# STM32H7RSxx register map
File version: 0.2
CPU: CM7 r0p1, little endian, MPU, FPU, 4 interrupt priority bits
Registers are 32-bit, read-write, reset 0x0 unless marked. A register's access mark holds for its fields unless they carry their own. Offsets are from the block's base; [hi:lo] are bit positions; lines under a group give offsets from that group; {n}, {i} and the like mark numbered series; 'fields as' and 'values as' point back to an identical list.

## ETH (part 2 of 4) — Ethernet register block
Base 0x40028000
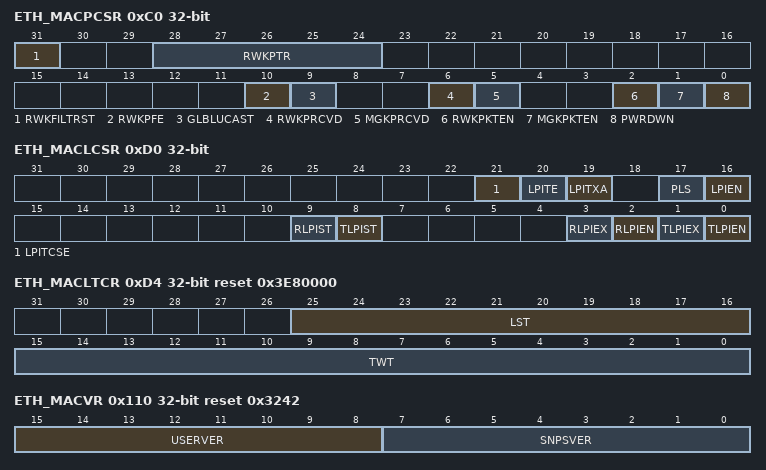
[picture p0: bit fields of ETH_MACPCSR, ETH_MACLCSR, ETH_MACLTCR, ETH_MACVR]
0xC0 ETH_MACPCSR access per field — PMT control status register
  [31] RWKFILTRST rw — Remote wakeup Packet Filter Register Pointer Reset When this bit is set, the remote wakeup packet filter register pointer is reset to 0. It is automatically cleared after 1 clock cycle.
  [28:24] RWKPTR ro — Remote wakeup FIFO Pointer This field gives the current value (0 to 7) of the Remote wakeup Packet Filter register pointer. When the value of this pointer is equal to 7, the contents of the Remote wakeup Packet Filter Register are transferred to the eth_mii_rx_clk domain when a Write occurs to that register.
  [10] RWKPFE rw — Remote wakeup Packet Forwarding Enable When this bit is set along with RWKPKTEN, the MAC receiver drops all received frames until it receives the expected wakeup frame. All frames after that event including the received wakeup frame are forwarded to application. This bit is then self-cleared on receiving the wakeup packet. The application can also clear this bit before the expected wakeup frame is received. In such cases, the MAC reverts to the default behavior where packets received are forwarded to the application. This bit must only be set when RWKPKTEN is set high and PWRDWN is set low. The setting of this bit has no effect when PWRDWN is set high. Note: If Magic Packet Enable and wakeup Frame Enable are both set along with setting of this bit and Magic Packet is received prior to wakeup frame, this bit is self-cleared on receiving Magic Packet, the received Magic packet is dropped, and all frames after received Magic Packet are forwarded to application.
  [9] GLBLUCAST rw — Global Unicast When this bit set, any unicast packet filtered by the MAC (DAF) address recognition is detected as a remote wakeup packet.
  [6] RWKPRCVD ro — Remote wakeup Packet Received When this bit is set, it indicates that the power management event is generated because of the reception of a remote wakeup packet. This bit is cleared when this register is read.
  [5] MGKPRCVD rw read-clears — Magic Packet Received When this bit is set, it indicates that the power management event is generated because of the reception of a magic packet. This bit is cleared when this register is read (or write of 1 when RCWE bit in CSR software control register (ETH_MACCSRSWCR) is set).
  [2] RWKPKTEN rw — Remote wakeup Packet Enable When this bit is set, a power management event is generated when the MAC receives a remote wakeup packet.
  [1] MGKPKTEN rw — Magic Packet Enable When this bit is set, a power management event is generated when the MAC receives a magic packet.
  [0] PWRDWN rw — Power Down When this bit is set, the MAC receiver drops all received packets until it receives the expected magic packet or remote wakeup packet. This bit is then self-cleared and the power-down mode is disabled. The software can clear this bit before the expected magic packet or remote wakeup packet is received. The packets received by the MAC after this bit is cleared are forwarded to the application. This bit must only be set when the Magic Packet Enable, Global Unicast, or Remote wakeup Packet Enable bit is set high. Note: You can gate-off the CSR clock during the power-down mode. However, when the CSR clock is gated-off, you cannot perform any read or write operations on this register. Therefore, the Software cannot clear this bit.
0xC4 ETH_MACRWKPFR — Remote wakeup packet filter register
  [31:0] MACRWKPFR — Remote wakeup packet filter Refer to Table 532, Table 533 and Table 534 for details on register content and programming sequence.
0xD0 ETH_MACLCSR access per field — LPI control and status register
  [21] LPITCSE rw — LPI Tx Clock Stop Enable When this bit is set, the MAC asserts sbd_tx_clk_gating_ctrl_o signal high after it enters Tx LPI mode to indicate that the Tx clock to MAC can be stopped. When this bit is reset, the MAC does not assert sbd_tx_clk_gating_ctrl_o signal high after it enters Tx LPI mode. If RGMII Interface is selected, the Tx clock is required for transmitting the LPI pattern. The Tx Clock cannot be gated and so the LPITCSE bit cannot be programmed.
  [20] LPITE rw — LPI Timer Enable This bit controls the automatic entry of the MAC Transmitter into and exit out of the LPI state. When LPITE, LPITXA and LPIEN bits are set, the MAC Transmitter enters LPI state only when the complete MAC TX data path is IDLE for a period indicated by the ETH_MACLETR register. After entering LPI state, if the data path becomes non-IDLE (due to a new packet being accepted for transmission), the Transmitter exits LPI state but does not clear LPIEN bit. This enables the re-entry into LPI state when it is IDLE again. When LPITE is 0, the LPI Auto timer is disabled and MAC Transmitter enters LPI state based on the settings of LPITXA and LPIEN bit descriptions.
  [19] LPITXA rw — LPI Tx Automate This bit controls the behavior of the MAC when it is entering or coming out of the LPI mode on the Transmit side. If the LPITXA and LPIEN bits are set to 1, the MAC enters the LPI mode only after all outstanding packets (in the core) and pending packets (in the application interface) have been transmitted. The MAC comes out of the LPI mode when the application sends any packet for transmission or the application issues a Tx FIFO Flush command. In addition, the MAC automatically clears the LPIEN bit when it exits the LPI state. If Tx FIFO Flush is set in the FTQ bit of ETH_MTLTxQOMR, when the MAC is in the LPI mode, it exits the LPI mode. When this bit is 0, the LPIEN bit directly controls behavior of the MAC when it is entering or coming out of the LPI mode.
  [17] PLS rw — PHY Link Status This bit indicates the link status of the PHY. The MAC Transmitter asserts the LPI pattern only when the link status is up (OKAY) at least for the time indicated by the LPI LS TIMER. When this bit is set, the link is considered to be okay (UP) and when this bit is reset, the link is considered to be down.
  [16] LPIEN rw — LPI Enable When this bit is set, it instructs the MAC Transmitter to enter the LPI state. When this bit is reset, it instructs the MAC to exit the LPI state and resume normal transmission. This bit is cleared when the LPITXA bit is set and the MAC exits the LPI state because of the arrival of a new packet for transmission.
  [9] RLPIST ro — Receive LPI State When this bit is set, it indicates that the MAC is receiving the LPI pattern on the MII interface.
  [8] TLPIST ro — Transmit LPI State When this bit is set, it indicates that the MAC is transmitting the LPI pattern on the MII interface.
  [3] RLPIEX ro — Receive LPI Exit When this bit is set, it indicates that the MAC Receiver has stopped receiving the LPI pattern on the MII interface, exited the LPI state, and resumed the normal reception. This bit is cleared by a read into this register (or write of 1 when RCWE bit in CSR software control register (ETH_MACCSRSWCR) is set). Note: This bit may not be set if the MAC stops receiving the LPI pattern for a very short duration, such as, less than three clock cycles of CSR clock.
  [2] RLPIEN ro — Receive LPI Entry When this bit is set, it indicates that the MAC Receiver has received an LPI pattern and entered the LPI state. This bit is cleared by a read into this register (or write of 1 when RCWE bit in CSR software control register (ETH_MACCSRSWCR) is set). Note: This bit may not be set if the MAC stops receiving the LPI pattern for a very short duration, such as, less than three clock cycles of CSR clock.
  [1] TLPIEX ro — Transmit LPI Exit When this bit is set, it indicates that the MAC transmitter exited the LPI state after the application cleared the LPIEN bit and the LPI TW Timer has expired. This bit is cleared by a read into this register (or write of 1 when RCWE bit in CSR software control register (ETH_MACCSRSWCR) is set).
  [0] TLPIEN ro — Transmit LPI Entry When this bit is set, it indicates that the MAC Transmitter has entered the LPI state because of the setting of the LPIEN bit. This bit is cleared by a read into this register (or write of 1 when RCWE bit in CSR software control register (ETH_MACCSRSWCR) is set).
0xD4 ETH_MACLTCR reset 0x3E80000 — LPI timers control register
  [25:16] LST — LPI LS Timer This field specifies the minimum time (in milliseconds) for which the link status from the PHY should be up (OKAY) before the LPI pattern can be transmitted to the PHY. The MAC does not transmit the LPI pattern even when the LPIEN bit is set unless the LPI LS Timer reaches the programmed terminal count. The default value of the LPI LS Timer is 1000 (1 sec) as defined in the IEEE standard.
  [15:0] TWT — LPI TW Timer This field specifies the minimum time (in microseconds) for which the MAC waits after it stops transmitting the LPI pattern to the PHY and before it resumes the normal transmission. The TLPIEX status bit is set after the expiry of this timer.
0xD8 ETH_MACLETR — LPI entry timer register
  [19:0] LPIET — LPI Entry Timer This field specifies the time in microseconds the MAC waits to enter LPI mode, after it has transmitted all the frames. This field is valid and used only when LPITE and LPITXA are set to 1. Bits [2:0] are read-only so that the granularity of this timer is in steps of 8 micro-seconds.
0xDC ETH_MAC1USTCR — One-microsecond-tick counter register
  [11:0] TIC_1US_CNTR — 1 �s tick Counter The application must program this counter so that the number of clock cycles of CSR clock is 1 �s (subtract 1 from the value before programming). For example if the CSR clock is 100 MHz then this field needs to be programmed to 100 - 1 = 99 (which is 0x63). This is required to generate the 1 �s events that are used to update some of the EEE related counters.
0x110 ETH_MACVR ro reset 0x3242 — Version register
  [15:8] USERVER — ST-defined version
  [7:0] SNPSVER — IP version
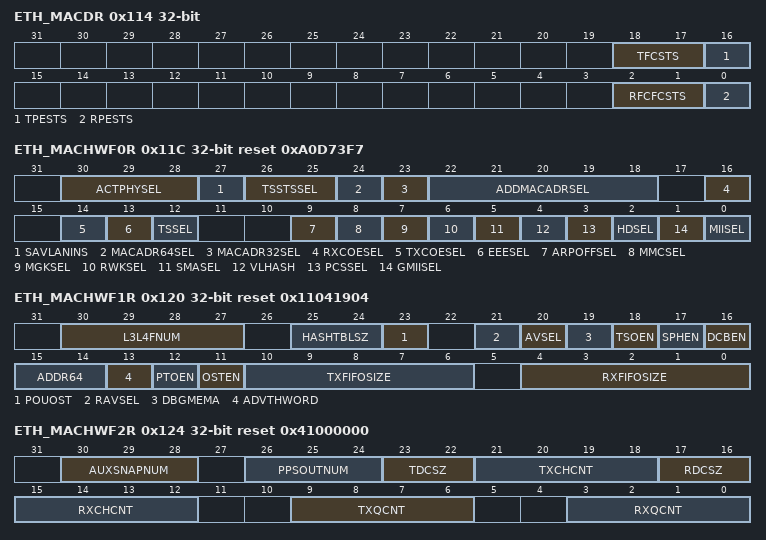
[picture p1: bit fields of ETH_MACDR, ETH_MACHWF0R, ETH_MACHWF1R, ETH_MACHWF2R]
0x114 ETH_MACDR ro — Debug register
  [18:17] TFCSTS — MAC Transmit Packet Controller Status This field indicates the state of the MAC Transmit Packet Controller module: Status of the previous packet IPG or backoff period to be over
    0=Idle state; 1=Waiting for one of the following:; 2=Generating and transmitting a Pause control packet (in Full-duplex mode); 3=Transferring input packet for transmission
  [16] TPESTS — MAC MII Transmit Protocol Engine Status When this bit is set, it indicates that the MAC MII transmit protocol engine is actively transmitting data, and it is not in the Idle state.
  [2:1] RFCFCSTS — MAC Receive Packet Controller FIFO Status When this bit is set, this field indicates the active state of the small FIFO Read and Write controllers of the MAC Receive Packet Controller module.
  [0] RPESTS — MAC MII Receive Protocol Engine Status When this bit is set, it indicates that the MAC MII receive protocol engine is actively receiving data, and it is not in the Idle state.
0x11C ETH_MACHWF0R ro reset 0xA0D73F7 — HW feature 0 register
  [30:28] ACTPHYSEL — Active PHY Selected When you have multiple PHY interfaces in your configuration, this field indicates the sampled value of phy_intf_sel_i during reset de-assertion: Others: Reserved, must not be used
    0=GMII or MII; 1=RGMII; 2=SGMII; 3=TBI; 4=RMII; 5=RTBI; 6=SMII
  [27] SAVLANINS — Source Address or VLAN Insertion Enable This bit is set to 1 when the Enable SA and VLAN Insertion on Tx option is selected
  [26:25] TSSTSSEL — Timestamp System Time Source This bit indicates the source of the Timestamp system time: This bit is set to 1 when the Enable IEEE 1588 Timestamp Support option is selected
    1=Internal; 2=External; 3=Both; 0=Reserved, must not be used
  [24] MACADR64SEL — MAC Addresses 64-127 Selected This bit is set to 1 when the Enable Additional 64 MAC Address Registers (64-127) option is selected
  [23] MACADR32SEL — MAC Addresses 32-63 Selected This bit is set to 1 when the Enable Additional 32 MAC Address Registers (32-63) option is selected
  [22:18] ADDMACADRSEL — MAC Addresses 1-31 Selected This bit is set to 1 when the Enable Additional 1-31 MAC Address Registers option is selected
  [16] RXCOESEL — Receive Checksum Offload Enabled This bit is set to 1 when the Enable Receive TCP/IP Checksum Check option is selected
  [14] TXCOESEL — Transmit Checksum Offload Enabled This bit is set to 1 when the Enable Transmit TCP/IP Checksum Insertion option is selected
  [13] EEESEL — Energy Efficient Ethernet Enabled This bit is set to 1 when the Enable Energy Efficient Ethernet (EEE) option is selected
  [12] TSSEL — IEEE 1588-2008 Timestamp Enabled This bit is set to 1 when the Enable IEEE 1588 Timestamp Support option is selected
  [9] ARPOFFSEL — ARP Offload Enabled This bit is set to 1 when the Enable IPv4 ARP Offload option is selected
  [8] MMCSEL — RMON Module Enable This bit is set to 1 when the Enable MAC management counters (MMC) option is selected
  [7] MGKSEL — PMT Magic Packet Enable This bit is set to 1 when the Enable Magic Packet Detection option is selected
  [6] RWKSEL — PMT Remote Wakeup Packet Enable This bit is set to 1 when the Enable Remote wakeup Packet Detection option is selected
  [5] SMASEL — SMA (MDIO) Interface This bit is set to 1 when the Enable Station Management (MDIO Interface) option is selected
  [4] VLHASH — VLAN Hash Filter Selected This bit is set to 1 when the Enable VLAN Hash Table Based Filtering option is selected
  [3] PCSSEL — PCS Registers (TBI, SGMII, or RTBI PHY interface) This bit is set to 1 when the TBI, SGMII, or RTBI PHY interface option is selected
  [2] HDSEL — Half-duplex Support This bit is set to 1 when the Half-duplex mode is selected
  [1] GMIISEL — 1000 Mbps Support This bit is set to 1 when 1000 Mbps is selected as operating mode.
  [0] MIISEL — 10 or 100 Mbps Support This bit is set to 1 when 10/100 Mbps is selected as operating mode.
0x120 ETH_MACHWF1R ro reset 0x11041904 — HW feature 1 register
  [30:27] L3L4FNUM — Total number of L3 or L4 Filters This field indicates the total number of L3 or L4 filters: ..
    0=No L3 or L4 Filter; 1=1 L3 or L4 Filter; 2=2 L3 or L4 Filters; 8=8 L3 or L4
  [25:24] HASHTBLSZ — Hash Table Size This field indicates the size of the Hash table:
    0=No Hash table; 1=64; 2=128; 3=256
  [23] POUOST — One Step for PTP over UDP/IP Feature Enable This bit is set to 1 when the Enable one step timestamp for PTP over UDP/IP feature is selected.
  [21] RAVSEL — Rx Side Only AV Feature Enable This bit is set to 1 when the Enable Audio video bridging option on Rx Side Only is selected.
  [20] AVSEL — AV Feature Enable This bit is set to 1 when the Enable Audio video bridging option is selected.
  [19] DBGMEMA — DMA Debug Registers Enable This bit is set to 1 when the Debug Mode Enable option is selected
  [18] TSOEN — TCP Segmentation Offload Enable This bit is set to 1 when the Enable TCP Segmentation Offloading for TCP/IP Packets option is selected
  [17] SPHEN — Split Header Feature Enable This bit is set to 1 when the Enable Split Header Structure option is selected
  [16] DCBEN — DCB Feature Enable This bit is set to 1 when the Enable Data Center Bridging option is selected
  [15:14] ADDR64 — Address width This field indicates the configured address width. Others: Reserved, must not be used
    0=32 bits
  [13] ADVTHWORD — IEEE 1588 High Word Register Enable This bit is set to 1 when the Add IEEE 1588 Higher Word Register option is selected
  [12] PTOEN — PTP Offload Enable This bit is set to 1 when the Enable PTP Timestamp Offload Feature is selected.
  [11] OSTEN — One-Step Timestamping Enable This bit is set to 1 when the Enable One-Step Timestamp Feature is selected.
  [10:6] TXFIFOSIZE — MTL Transmit FIFO Size This field contains the configured value of MTL Tx FIFO in bytes expressed as Log to base 2 minus 7, that is, Log2(TXFIFO_SIZE) -7: 01011 to 11111: Reserved, must not be used
    0=128 bytes; 1=256 bytes; 2=512 bytes; 3=1,024 bytes; 4=2,048 bytes; 5=4,096 bytes; 6=8,192 bytes; 7=16,384 bytes; 8=32 Kbytes; 9=64 Kbytes; 10=128 Kbytes
  [4:0] RXFIFOSIZE — MTL Receive FIFO Size This field contains the configured value of MTL Rx FIFO in bytes expressed as Log to base 2 minus 7, that is, Log2(RXFIFO_SIZE) -7: 01100 to 11111: Reserved, must not be used
    0=128 bytes; 1=256 bytes; 2=512 bytes; 3=1,024 bytes; 4=2,048 bytes; 5=4,096 bytes; 6=8,192 bytes; 7=16,384 bytes; 8=32 Kbytes; 9=64 Kbytes; 10=128 Kbytes; 11=256 Kbytes
0x124 ETH_MACHWF2R ro reset 0x41000000 — HW feature 2 register
  [30:28] AUXSNAPNUM — Number of Auxiliary Snapshot Inputs This field indicates the number of auxiliary snapshot inputs: 101 to 111: Reserved, must not be used
    0=No auxiliary input; 1=1 auxiliary input; 2=2 auxiliary inputs; 3=3 auxiliary inputs; 4=4 auxiliary inputs
  [26:24] PPSOUTNUM — Number of PPS Outputs This field indicates the number of PPS outputs: 101 to 111: Reserved, must not be used
    0=No PPS output; 1=1 PPS output; 2=2 PPS outputs; 3=3 PPS outputs; 4=4 PPS outputs
  [23:22] TDCSZ — Tx DMA Descriptor Cache Size in terms of 16-byte descriptors
    0=Cache not configured; 1=Four 16-byte descriptors; 2=Eight 16-byte descriptors; 3=Sixteen 16-byte descriptors
  [21:18] TXCHCNT — Number of DMA Transmit Channels This field indicates the number of DMA Transmit channels: ..
    0=1 DMA Tx Channel; 1=2 DMA Tx Channels; 7=8 DMA Tx
  [17:16] RDCSZ — Rx DMA Descriptor Cache Size in terms of 16-byte descriptors
    values as TDCSZ
  [15:12] RXCHCNT — Number of DMA Receive Channels This field indicates the number of DMA Receive channels: ..
    0=1 DMA Rx Channel; 1=2 DMA Rx Channels; 7=8 DMA Rx
  [9:6] TXQCNT — Number of MTL Transmit Queues This field indicates the number of MTL Transmit queues: ..
    0=1 MTL Tx queue; 1=2 MTL Tx queues; 7=8 MTL Tx
  [3:0] RXQCNT — Number of MTL Receive Queues This field indicates the number of MTL Receive queues: ..
    0=1 MTL Rx queue; 1=2 MTL Rx queues; 7=8 MTL Rx
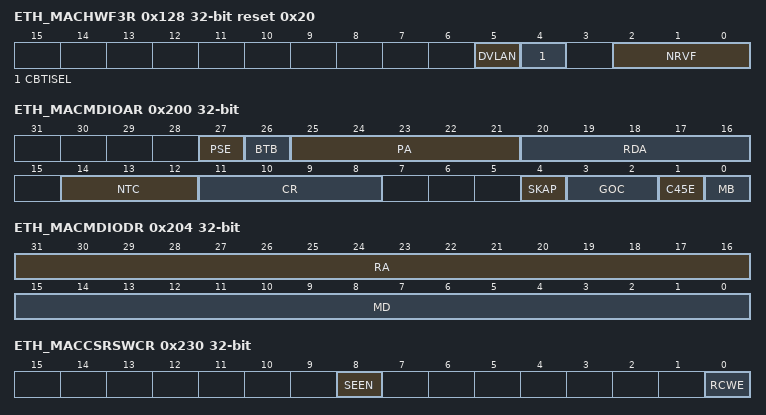
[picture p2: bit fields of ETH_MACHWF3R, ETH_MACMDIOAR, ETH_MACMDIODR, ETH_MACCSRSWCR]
0x128 ETH_MACHWF3R ro reset 0x20 — HW feature 3 register
  [5] DVLAN — Double VLAN processing enable This bit is set to 1 when Double VLAN processing is enabled.
  [4] CBTISEL — Queue/Channel based VLAN tag insertion on Tx enable This bit is set to 1 when the Enable Queue/Channel based VLAN tag insertion on Tx feature is selected.
  [2:0] NRVF — Number of Extended VLAN Tag Filters Enabled This field indicates the Number of Extended VLAN Tag Filters selected: 110 to 111: Reserved, must not be used
    0=No Extended Rx VLAN Filters; 1=4 Extended Rx VLAN Filters; 2=8 Extended Rx VLAN Filters; 3=16 Extended Rx VLAN Filters; 4=24 Extended Rx VLAN Filters; 5=32 Extended Rx VLAN Filters
0x200 ETH_MACMDIOAR — MDIO address register
  [27] PSE — Preamble Suppression Enable When this bit is set, the SMA suppresses the 32-bit preamble and transmit MDIO frames with only 1 preamble bit. When this bit is 0, the MDIO frame always has 32 bits of preamble as defined in the IEEE specifications.
  [26] BTB — Back to Back transactions When this bit is set and the NTC has value greater than 0, then the MAC informs the completion of a read or write command at the end of frame transfer (before the trailing clocks are transmitted). The software can thus initiate the next command which is executed immediately irrespective of the number trailing clocks generated for the previous frame. When this bit is reset, then the read/write command completion (MII busy is cleared) only after the trailing clocks are generated. In this mode, it is ensured that the NTC is always generated after each frame. This bit must not be set when NTC=0.
  [25:21] PA — Physical Layer Address This field indicates which Clause 22 PHY devices (out of 32 devices) the MAC is accessing. This field indicates which Clause 45 capable PHYs (out of 32 PHYs) the MAC is accessing.
  [20:16] RDA — Register/Device Address These bits select the PHY register in selected Clause 22 PHY device. These bits select the Device (MMD) in selected Clause 45 capable PHY.
  [14:12] NTC — Number of Training Clocks This field controls the number of trailing clock cycles generated on ETH_MDC after the end of transmission of MDIO frame. The valid values can be from 0 to 7. Programming the value to 011 indicates that there are additional three clock cycles on the MDC line after the end of MDIO frame transfer.
  [11:8] CR — CSR Clock Range The CSR Clock Range selection determines the frequency of the MDC clock according to the CSR clock frequency used in your design: 0110 to 0111: Reserved, must not be used The suggested range of CSR clock frequency applicable for each value (when Bit 11 = 0) ensures that the MDC clock is approximately between 1.0 MHz to 2.5 MHz frequency range. When Bit 11 is set, you can achieve a higher frequency of the MDC clock than the frequency limit of 2.5 MHz (specified in the IEEE 802.3) and program a clock divider of lower value. For example, when CSR clock is of 100 MHz frequency and you program these bits to 1010, the resultant MDC clock is of 12.5 MHz which is above the range specified in IEEE 802.3. Program the following values only if the interfacing chips support faster MDC clocks:
    0=CSR clock = 60-100 MHz; MDC clock = CSR clock/42; 1=CSR clock = 100-150 MHz; MDC clock = CSR clock/62; 2=CSR clock = 20-35 MHz; MDC clock = CSR clock/16; 3=CSR clock = 35-60 MHz; MDC clock = CSR clock/26; 4=CSR clock = 150-250 MHz; MDC clock = CSR clock/102; 5=CSR clock = 250-300 MHz; MDC clock = CSR clock/124; 8=CSR clock/4; 9=CSR clock/6; 10=CSR clock/8; 11=CSR clock/10; 12=CSR clock/12; 13=CSR clock/14; 14=CSR clock/16; 15=CSR clock/18
  [4] SKAP — Skip Address Packet When this bit is set, the SMA does not send the address packets before read, write, or post-read increment address packets. This bit is valid only when C45E is set.
  [3:2] GOC — MII Operation Command This bit indicates the operation command to the PHY. When Clause 22 PHY is enabled, only Write and Read commands are valid.
    0=Reserved, must not be used; 1=Write; 2=Post Read Increment Address for Clause 45 PHY; 3=Read
  [1] C45E — Clause 45 PHY Enable When this bit is set, Clause 45 capable PHY is connected to MDIO. When this bit is reset, Clause 22 capable PHY is connected to MDIO.
  [0] MB — MII Busy The application sets this bit to instruct the SMA to initiate a Read or Write access to the MDIOS. The MAC clears this bit after the MDIO frame transfer is completed. Hence the software must not write or change any of the fields in MDIO address register (ETH_MACMDIOAR) and MDIO data register (ETH_MACMDIODR) as long as this bit is set. For write transfers, the application must first write 16-bit data in the MD field (and also RA field when C45E is set) in MDIO data register (ETH_MACMDIODR) register before setting this bit. When C45E is set, it should also write into the RA field of MDIO data register (ETH_MACMDIODR) before initiating a read transfer. When a read transfer is completed (MII busy=0), the data read from the PHY register is valid in the MD field of the MDIO data register (ETH_MACMDIODR). Note: Even if the addressed PHY is not present, there is no change in the functionality of this bit.
0x204 ETH_MACMDIODR — MDIO data register
  [31:16] RA — Register Address This field is valid only when C45E is set. It contains the Register Address in the PHY to which the MDIO frame is intended for.
  [15:0] MD — MII Data This field contains the 16-bit data value read from the PHY after a Management Read operation or the 16-bit data value to be written to the PHY before a Management Write operation.
0x210 ETH_MACARPAR — ARP address register
  [31:0] ARPPA — ARP Protocol Address This field contains the IPv4 Destination Address of the MAC. This address is used for perfect match with the Protocol Address of Target field in the received ARP packet.
0x230 ETH_MACCSRSWCR — CSR software control register
  [8] SEEN — Slave Error Response Enable When this bit is set, the MAC responds with a Slave Error for accesses to reserved registers in CSR space. When this bit is reset, the MAC responds with an Okay response to any register accessed from CSR space.
  [0] RCWE — Register Clear on Write 1 Enable When this bit is set, the access mode to some register fields changes to rc_w1 (clear on write) meaning that the application needs to set that respective bit to 1 to clear it. When this bit is reset, the access mode to these register fields remains rc_r (clear on read).
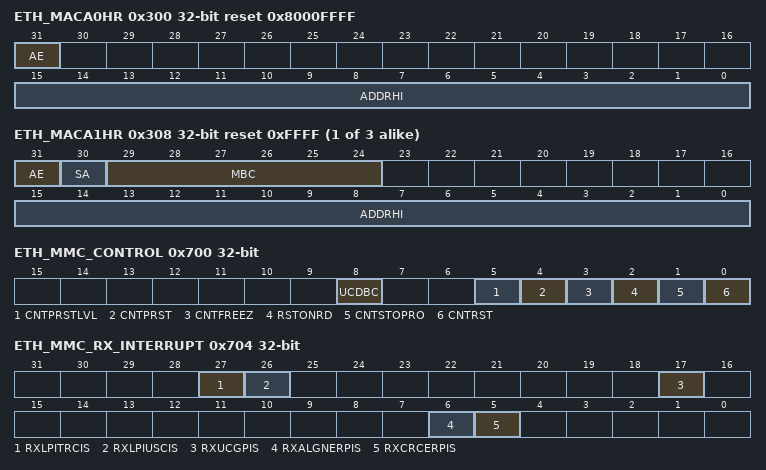
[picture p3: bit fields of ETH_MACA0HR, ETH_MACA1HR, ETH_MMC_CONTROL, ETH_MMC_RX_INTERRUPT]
0x300 ETH_MACA0HR access per field reset 0x8000FFFF — MAC Address 0 high register
  [31] AE ro — Address Enable This bit is always set to 1.
  [15:0] ADDRHI rw — MAC Address0[47:32] This field contains the upper 16 bits [47:32] of the first 6-byte MAC address. The MAC uses this field for filtering the received packets and inserting the MAC address in the Transmit Flow Control (Pause) Packets.
{0x304+8i} ETH_MACA{i}LR reset 0xFFFFFFFF (i=0..3) — MAC Address {i} low register
  [31:0] ADDRLO — MAC Address x [31:0] This field contains the lower 32 bits of the first 6-byte MAC address. The MAC uses this field for filtering the received packets and inserting the MAC address in the Transmit Flow Control (Pause) Packets.
{0x300+8i} ETH_MACA{i}HR reset 0xFFFF (i=1..3) — MAC Address {i} high register
  [31] AE — Address Enable When this bit is set, the address filter module uses the second MAC address for perfect filtering. When this bit is reset, the address filter module ignores the address for filtering.
  [30] SA — Source Address When this bit is set, the MAC Addressx[47:0] is used to compare with the SA fields of the received packet. When this bit is reset, the MAC Address x[47:0] is used to compare with the DA fields of the received packet.
    0=DA; 1=SA
  [29:24] MBC — Mask Byte Control These bits are mask control bits for comparing each of the MAC Address bytes. When set high, the MAC does not compare the corresponding byte of received DA or SA with the contents of MAC Address1 registers. Each bit controls the masking of the bytes as follows: Bit 29: ETH_MACAxHR[15:8] Bit 28: ETH_MACAxHR[7:0] Bit 27: ETH_MACAxLR[31:24] Bit 26: ETH_MACAxLR[23:16] Bit 25: ETH_MACAxLR[15:8] Bit 24: ETH_MACAxLR[7:0] You can filter a group of addresses (known as group address filtering) by masking one or more bytes of the address.
  [15:0] ADDRHI — MAC Address1 [47:32] This field contains the upper 16 bits[47:32] of the second 6-byte MAC address.
0x700 ETH_MMC_CONTROL — MMC control register
  [8] UCDBC — Update MMC Counters for Dropped Broadcast Packets The CNTRST bit has a higher priority than the CNTPRST bit. Therefore, when the software tries to set both bits in the same write cycle, all counters are cleared and the CNTPRST bit is not set. When set, the MAC updates all related MMC Counters for Broadcast packets that are dropped because of the setting of the DBF bit of Packet filtering control register (ETH_MACPFR). When reset, the MMC Counters are not updated for dropped Broadcast packets.
  [5] CNTPRSTLVL — Full-Half Preset When this bit is low and the CNTPRST bit is set, all MMC counters get preset to almost-half value. All octet counters get preset to 0x7FFF_F800 (Half 2Kbytes) and all packet-counters get preset to 0x7FFF_FFF0 (Half 16). When this bit is high and the CNTPRST bit is set, all MMC counters get preset to almost-full value. All octet counters get preset to 0xFFFF_F800 (Full 2Kbytes) and all packet-counters get preset to 0xFFFF_FFF0 (Full 16). For 16-bit counters, the almost-half preset values are 0x7800 and 0x7FF0 for the respective octet and packet counters. Similarly, the almost-full preset values for the 16-bit counters are 0xF800 and 0xFFF0.
  [4] CNTPRST — Counters Preset When this bit is set, all counters are initialized or preset to almost full or almost half according to the CNTPRSTLVL bit. This bit is cleared automatically after 1 clock cycle. This bit, along with the CNTPRSTLVL bit, is useful for debugging and testing the assertion of interrupts because of MMC counter becoming half-full or full.
  [3] CNTFREEZ — MMC Counter Freeze When this bit is set, it freezes all MMC counters to their current value. Until this bit is reset to 0, no MMC counter is updated because of any transmitted or received packet. If any MMC counter is read with the Reset on Read bit set, then that counter is also cleared in this mode.
  [2] RSTONRD — Reset on Read When this bit is set, the MMC counters are reset to zero after Read (self-clearing after reset). The counters are cleared when the least significant byte lane (Bits[7:0]) is read.
  [1] CNTSTOPRO — Counter Stop Rollover When this bit is set, the counter does not roll over to zero after reaching the maximum value.
  [0] CNTRST — Counters Reset When this bit is set, all counters are reset. This bit is cleared automatically after 1 clock cycle.
0x704 ETH_MMC_RX_INTERRUPT — MMC Rx interrupt register
  [27] RXLPITRCIS read-clears — MMC Receive LPI transition counter interrupt status This bit is set when the Rx LPI transition counter register (ETH_RX_LPI_TRAN_CNTR) counter reaches half of the maximum value or the maximum value.
  [26] RXLPIUSCIS read-clears — MMC Receive LPI microsecond counter interrupt status This bit is set when the Rx LPI microsecond counter register (ETH_RX_LPI_USEC_CNTR) counter reaches half of the maximum value or the maximum value.
  [17] RXUCGPIS read-clears — MMC Receive Unicast Good Packet Counter Interrupt Status This bit is set when the Rx unicast packets good register (ETH_RX_UNICAST_PACKETS_GOOD) counter reaches half of the maximum value or the maximum value.
  [6] RXALGNERPIS read-clears — MMC Receive Alignment Error Packet Counter Interrupt Status This bit is set when the Rx alignment error packets register (ETH_RX_ALIGNMENT_ERROR_PACKETS) counter reaches half of the maximum value or the maximum value.
  [5] RXCRCERPIS read-clears — MMC Receive CRC Error Packet Counter Interrupt Status This bit is set when the Rx CRC error packets register (ETH_RX_CRC_ERROR_PACKETS) counter reaches half of the maximum value or the maximum value.
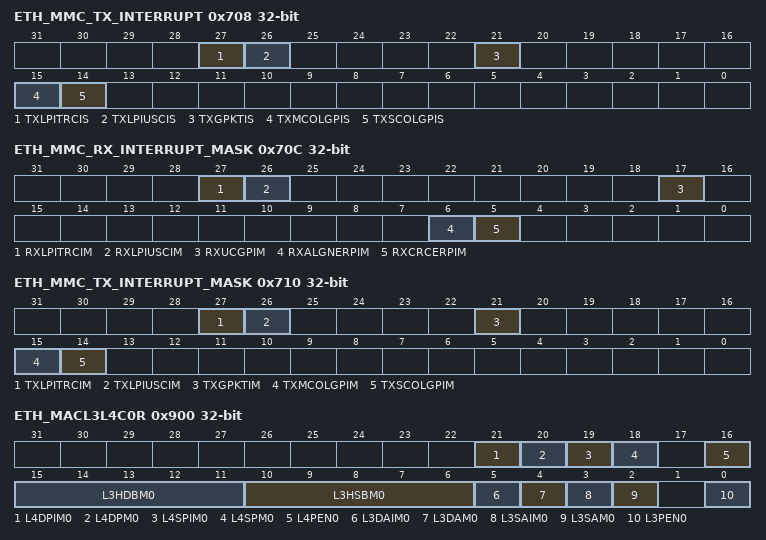
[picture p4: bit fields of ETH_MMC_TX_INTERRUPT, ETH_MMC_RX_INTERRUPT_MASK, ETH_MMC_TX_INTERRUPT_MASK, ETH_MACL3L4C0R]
0x708 ETH_MMC_TX_INTERRUPT — MMC Tx interrupt register
  [27] TXLPITRCIS read-clears — MMC Transmit LPI transition counter interrupt status This bit is set when the Tx LPI transition counter register (ETH_TX_LPI_TRAN_CNTR) counter reaches half of the maximum value or the maximum value.
  [26] TXLPIUSCIS read-clears — MMC Transmit LPI microsecond counter interrupt status This bit is set when the Tx LPI microsecond timer register (ETH_TX_LPI_USEC_CNTR) counter reaches half of the maximum value or the maximum value.
  [21] TXGPKTIS read-clears — MMC Transmit Good Packet Counter Interrupt Status This bit is set when the Tx packet count good register (ETH_TX_PACKET_COUNT_GOOD) counter reaches half of the maximum value or the maximum value.
  [15] TXMCOLGPIS read-clears — MMC Transmit Multiple Collision Good Packet Counter Interrupt Status This bit is set when the Tx multiple collision good packets register (ETH_TX_MULTIPLE_COLLISION_GOOD_PACKETS) counter reaches half of the maximum value or the maximum value.
  [14] TXSCOLGPIS read-clears — MMC Transmit Single Collision Good Packet Counter Interrupt Status This bit is set when the Tx single collision good packets register (ETH_TX_SINGLE_COLLISION_GOOD_PACKETS) counter reaches half of the maximum value or the maximum value.
0x70C ETH_MMC_RX_INTERRUPT_MASK — MMC Rx interrupt mask register
  [27] RXLPITRCIM — MMC Receive LPI transition counter interrupt Mask Setting this bit masks the interrupt when the Rx LPI transition counter register (ETH_RX_LPI_TRAN_CNTR) counter reaches half of the maximum value or the maximum value.
  [26] RXLPIUSCIM — MMC Receive LPI microsecond counter interrupt Mask Setting this bit masks the interrupt when the Rx LPI microsecond counter register (ETH_RX_LPI_USEC_CNTR) counter reaches half of the maximum value or the maximum value.
  [17] RXUCGPIM — MMC Receive Unicast Good Packet Counter Interrupt Mask Setting this bit masks the interrupt when the Rx unicast packets good register (ETH_RX_UNICAST_PACKETS_GOOD) counter reaches half of the maximum value or the maximum value.
  [6] RXALGNERPIM — MMC Receive Alignment Error Packet Counter Interrupt Mask Setting this bit masks the interrupt when the Rx alignment error packets register (ETH_RX_ALIGNMENT_ERROR_PACKETS) counter reaches half of the maximum value or the maximum value.
  [5] RXCRCERPIM — MMC Receive CRC Error Packet Counter Interrupt Mask Setting this bit masks the interrupt when the Rx CRC error packets register (ETH_RX_CRC_ERROR_PACKETS) counter reaches half of the maximum value or the maximum value.
0x710 ETH_MMC_TX_INTERRUPT_MASK — MMC Tx interrupt mask register
  [27] TXLPITRCIM — MMC Transmit LPI transition counter interrupt Mask Setting this bit masks the interrupt when the Tx LPI transition counter register (ETH_TX_LPI_TRAN_CNTR) counter reaches half of the maximum value or the maximum value.
  [26] TXLPIUSCIM — MMC Transmit LPI microsecond counter interrupt Mask Setting this bit masks the interrupt when the Tx LPI microsecond timer register (ETH_TX_LPI_USEC_CNTR) counter reaches half of the maximum value or the maximum value.
  [21] TXGPKTIM — MMC Transmit Good Packet Counter Interrupt Mask Setting this bit masks the interrupt when the Tx packet count good register (ETH_TX_PACKET_COUNT_GOOD) counter reaches half of the maximum value or the maximum value.
  [15] TXMCOLGPIM — MMC Transmit Multiple Collision Good Packet Counter Interrupt Mask Setting this bit masks the interrupt when the Tx multiple collision good packets register (ETH_TX_MULTIPLE_COLLISION_GOOD_PACKETS) counter reaches half of the maximum value or the maximum value.
  [14] TXSCOLGPIM — MMC Transmit Single Collision Good Packet Counter Interrupt Mask Setting this bit masks the interrupt when the Tx single collision good packets register (ETH_TX_SINGLE_COLLISION_GOOD_PACKETS) counter reaches half of the maximum value or the maximum value.
0x74C ETH_TX_SINGLE_COLLISION_GOOD_PACKETS ro — Tx single collision good packets register
  [31:0] TXSNGLCOLG — Tx Single Collision Good Packets This field indicates the number of successfully transmitted packets after a single collision in the Half-duplex mode.
0x750 ETH_TX_MULTIPLE_COLLISION_GOOD_PACKETS ro — Tx multiple collision good packets register
  [31:0] TXMULTCOLG — Tx Multiple Collision Good Packets This field indicates the number of successfully transmitted packets after multiple collisions in the Half-duplex mode.
0x768 ETH_TX_PACKET_COUNT_GOOD ro — Tx packet count good register
  [31:0] TXPKTG — Tx Packet Count Good This field indicates the number of good packets transmitted.
0x794 ETH_RX_CRC_ERROR_PACKETS ro — Rx CRC error packets register
  [31:0] RXCRCERR — Rx CRC Error Packets This field indicates the number of packets received with CRC error.
0x798 ETH_RX_ALIGNMENT_ERROR_PACKETS ro — Rx alignment error packets register
  [31:0] RXALGNERR — Rx Alignment Error Packets This field indicates the number of packets received with alignment (dribble) error. It is valid only in 10/100 mode.
0x7C4 ETH_RX_UNICAST_PACKETS_GOOD ro — Rx unicast packets good register
  [31:0] RXUCASTG — Rx Unicast Packets Good This field indicates the number of good unicast packets received.
0x7EC ETH_TX_LPI_USEC_CNTR ro — Tx LPI microsecond timer register
  [31:0] TXLPIUSC — Tx LPI Microseconds Counter This field indicates the number of microseconds Tx LPI is asserted. For every Tx LPI Entry and Exit, the Timer value can have an error of +/- 1 microsecond.
0x7F0 ETH_TX_LPI_TRAN_CNTR ro — Tx LPI transition counter register
  [31:0] TXLPITRC — Tx LPI Transition counter This field indicates the number of times Tx LPI Entry has occurred. Even if Tx LPI Entry occurs in Automate mode (because of LPITXA bit set in the LPI control and status register (ETH_MACLCSR)), the counter increments.
0x7F4 ETH_RX_LPI_USEC_CNTR ro — Rx LPI microsecond counter register
  [31:0] RXLPIUSC — Rx LPI Microseconds Counter This field indicates the number of microseconds Rx LPI is asserted. For every Rx LPI Entry and Exit, the Timer value can have an error of +/- 1 microsecond.
0x7F8 ETH_RX_LPI_TRAN_CNTR ro — Rx LPI transition counter register
  [31:0] RXLPITRC — Rx LPI Transition counter This field indicates the number of times Rx LPI Entry has occurred.
0x900 ETH_MACL3L4C0R — L3 and L4 control 0 register
  [21] L4DPIM0 — Layer 4 Destination Port Inverse Match Enable When this bit is set, the Layer 4 Destination Port number field is enabled for inverse matching. When this bit is reset, the Layer 4 Destination Port number field is enabled for perfect matching. This bit is valid and applicable only when the L4DPM0 bit is set high.
  [20] L4DPM0 — Layer 4 Destination Port Match Enable When this bit is set, the Layer 4 Destination Port number field is enabled for matching. When this bit is reset, the MAC ignores the Layer 4 Destination Port number field for matching.
  [19] L4SPIM0 — Layer 4 Source Port Inverse Match Enable When this bit is set, the Layer 4 Source Port number field is enabled for inverse matching. When this bit is reset, the Layer 4 Source Port number field is enabled for perfect matching. This bit is valid and applicable only when the L4SPM0 bit is set high.
  [18] L4SPM0 — Layer 4 Source Port Match Enable When this bit is set, the Layer 4 Source Port number field is enabled for matching. When this bit is reset, the MAC ignores the Layer 4 Source Port number field for matching.
  [16] L4PEN0 — Layer 4 Protocol Enable When this bit is set, the Source and Destination Port number fields of UDP packets are used for matching. When this bit is reset, the Source and Destination Port number fields of TCP packets are used for matching. The Layer 4 matching is done only when the L4SPM0 or L4DPM0 bit is set.
  [15:11] L3HDBM0 — Layer 3 IP DA higher bits match This field contains the number of higher bits of IP Destination Address that are masked in the IPv4 packets: .. Bits[12:11] of this field correspond to Bits[6:5] of L3HSBM0 which indicate the number of lower bits of IP Source or Destination Address that are masked in the IPv6 packets. Number of bits masked is given by concatenated values of the L3HDBM0[1:0] and L3HSBM0 bits: .. This field is valid and applicable only when the L3DAM0 or L3SAM0 bit is set.
    0=B_0x0_IPV4_PACKETS (No bits are masked.); 1=B_0x1_IPV4_PACKETS (LSb[0] is masked); 0=B_0x0_IPV6_PACKETS (No bits are masked.); 1=B_0x1_IPV6_PACKETS (LSb[0] is masked)
  [10:6] L3HSBM0 — Layer 3 IP SA higher bits match This field contains the number of lower bits of IP source address that are masked for matching in the IPv4 packets. The following list describes the values of this field: .. Condition: IPv6 packets: This field contains Bits[4:0] of L3HSBM0. These bits indicate the number of higher bits of IP source or destination address matched in the IPv6 packets. This field is valid and applicable only when the L3DAM0 or L3SAM0 bit is set high.
    0=B_0x0_IPV4_PACKETS (No bits are masked.); 1=B_0x1_IPV4_PACKETS (LSb[0] is masked)
  [5] L3DAIM0 — Layer 3 IP DA Inverse Match Enable When this bit is set, the Layer 3 IP Destination Address field is enabled for inverse matching. When this bit is reset, the Layer 3 IP Destination Address field is enabled for perfect matching. This bit is valid and applicable only when the L3DAM0 bit is set high.
  [4] L3DAM0 — Layer 3 IP DA Match Enable When this bit is set, the Layer 3 IP Destination Address field is enabled for matching. When this bit is reset, the MAC ignores the Layer 3 IP Destination Address field for matching. Note: When the L3PEN0 bit is set, you should set either this bit or the L3SAM0 bit because either IPv6 DA or SA can be checked for filtering.
  [3] L3SAIM0 — Layer 3 IP SA Inverse Match Enable When this bit is set, the Layer 3 IP Source Address field is enabled for inverse matching. When this bit reset, the Layer 3 IP Source Address field is enabled for perfect matching. This bit is valid and applicable only when the L3SAM0 bit is set.
  [2] L3SAM0 — Layer 3 IP SA Match Enable When this bit is set, the Layer 3 IP Source Address field is enabled for matching. When this bit is reset, the MAC ignores the Layer 3 IP Source Address field for matching. Note: When the L3PEN0 bit is set, you should set either this bit or the L3DAM0 bit because either IPv6 SA or DA can be checked for filtering.
  [0] L3PEN0 — Layer 3 Protocol Enable When this bit is set, the Layer 3 IP Source or Destination Address matching is enabled for IPv6 packets. When this bit is reset, the Layer 3 IP Source or Destination Address matching is enabled for IPv4 packets. The Layer 3 matching is done only when the L3SAM0 or L3DAM0 bit is set.
